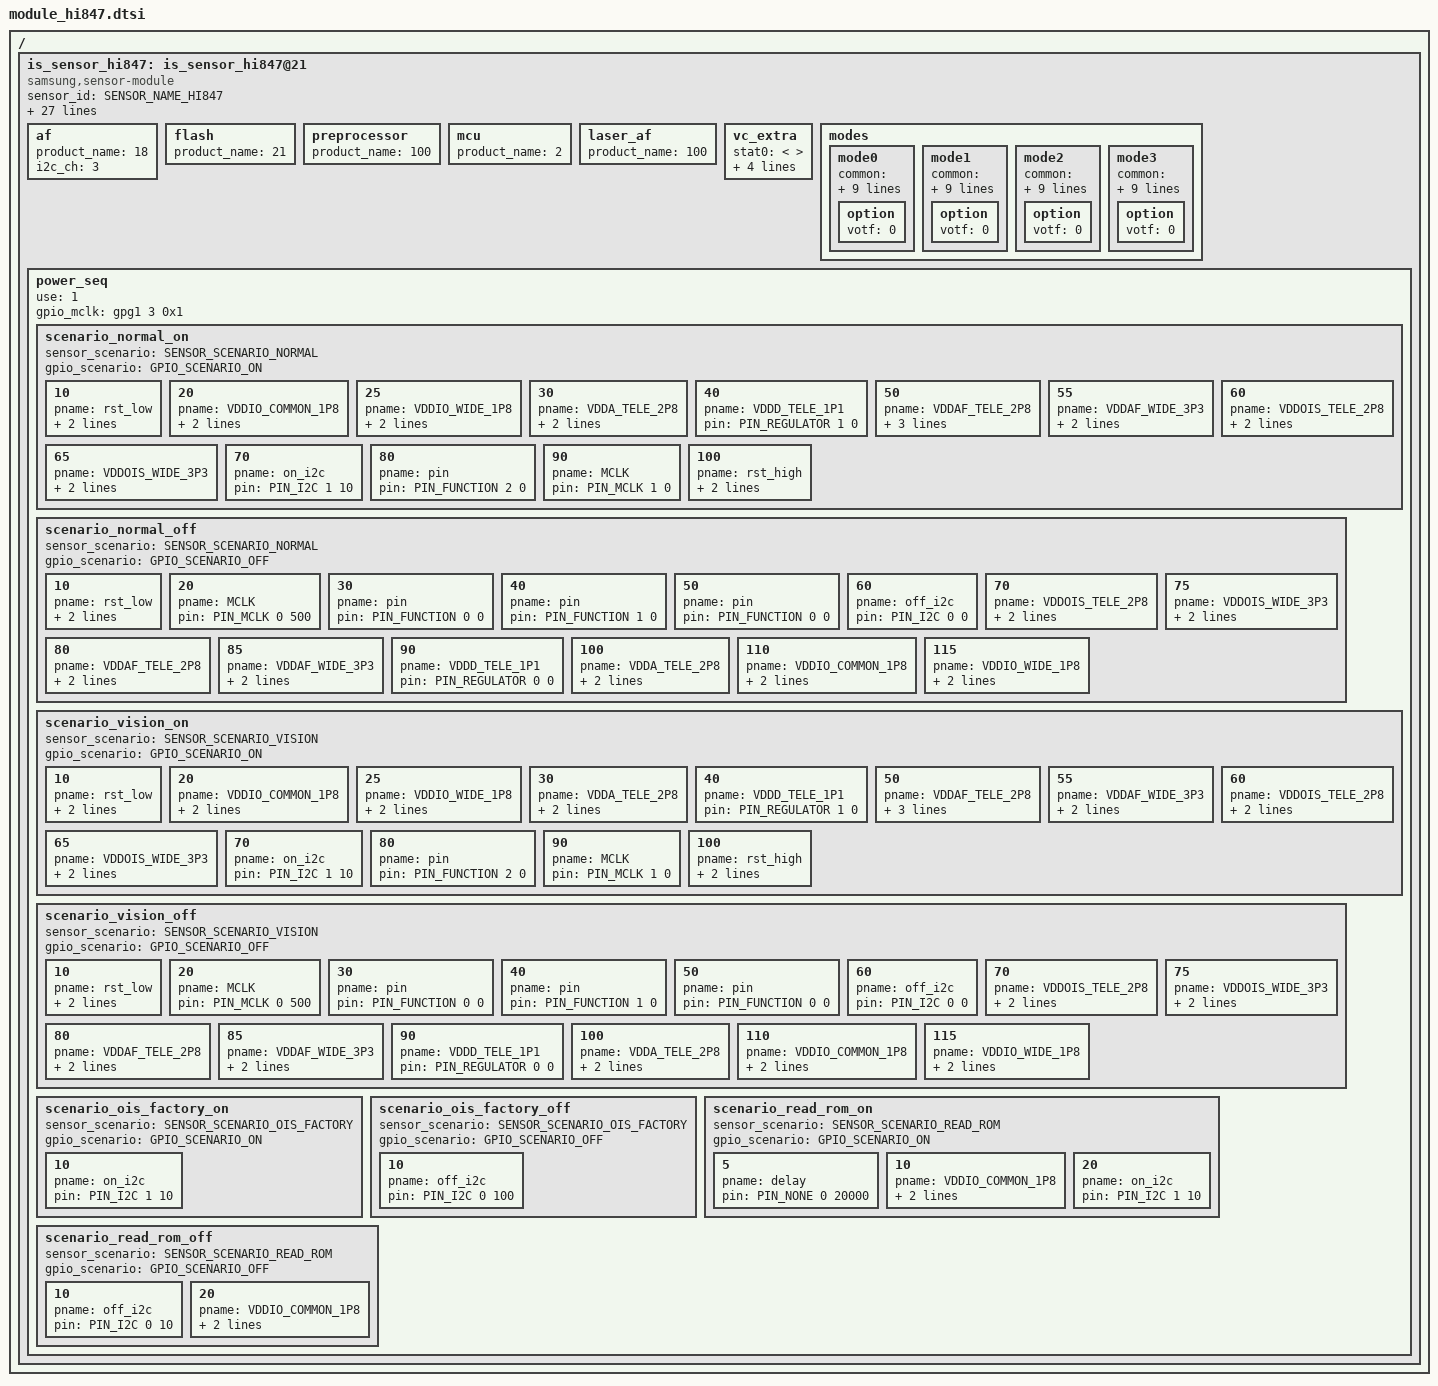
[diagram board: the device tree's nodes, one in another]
/*
 * SAMSUNG EXYNOSxxxx board camera device tree source
 *
 * Copyright (c) 2023 Samsung Electronics Co., Ltd.
 *		http://www.samsung.com
 *
 * This program is free software; you can redistribute it and/or modify
 * it under the terms of the GNU General Public License version 2 as
 * published by the Free Software Foundation.
 */

#include <dt-bindings/camera/exynos_is_dt.h>

/ {
	fragment@camera {
		target-path = "/";
		__overlay__ {
			is_sensor_hi847: is_sensor_hi847@21 {
				compatible = "samsung,sensor-module";

				/* common */
				sensor_id = <SENSOR_NAME_HI847>;
				active_width = <3264>;
				active_height = <2448>;
				margin_left = <0>;
				margin_right = <0>;
				margin_top = <0>;
				margin_bottom = <0>;
				max_framerate = <60>;
				bitwidth = <10>;
				use_retention_mode = <SENSOR_RETENTION_UNSUPPORTED>;
				sensor_maker = "HYNIX";
				sensor_name = "HI847";
				setfile_name = "setfile_hi847.bin";

				status = "okay";

				/* board */
				pinctrl-names = "pin0", "pin1", "pin2", "release";
				pinctrl-0 = <>;
				pinctrl-1 = <&sensor_mclk3_out>;
				pinctrl-2 = <&sensor_mclk3_fn>;
				pinctrl-3 = <>;

				position = <2>; /* Rear:0. Front:1, Tele:2 */
				id = <2>; /* is_sensor id */
				mclk_ch = <3>;
				mclk_freq = <19200>;
				sensor_i2c_ch = <2>; /* SENSOR_CONTROL_I2C2 */

				/* vendor */
				rom_type = <2>; /* ROM_TYPE_EEPROM */
				rom_id = <4>;
				rom_cal_index = <0>;
				rom_dualcal_id = <4>;
				rom_dualcal_index = <0>;

				/* peri */
				af {
					product_name = <18>; /* ACTUATOR_NAME_AK737X */
					i2c_ch = <3>; /* SENSOR_CONTROL_I2C3 */
				};

				flash {
					product_name = <21>;  /* AW36518 */
				};

				preprocessor {
					product_name = <100>; /* NOTHING */
				};

				mcu {
					product_name = <2>; /* INTERNAL */
				};

				laser_af {
					product_name = <100>; /* NOTHING */
				};

				vc_extra {
					/* ex) statX = <stat_type, sensor_mode, max_width, max_height, max_element> */
					stat0 = </* not available */>; /* VC_BUF_DATA_TYPE_SENSOR_STAT1 */
					stat1 = </*VC_STAT_TYPE_PDP_4_1_PDAF_STAT0*/ 1200 /*VC_SENSOR_MODE_ULTRA_PD_3_TAIL*/ 305 200 600 2>;
					stat2 = </* not available */>; /* VC_BUF_DATA_TYPE_SENSOR_STAT2 */
					stat3 = </*VC_STAT_TYPE_PDP_4_1_PDAF_STAT1*/ 1201 /*VC_SENSOR_MODE_ULTRA_PD_3_TAIL*/ 305 200 600 2>;
					stat_vc = <2>; /* STAT out VC after CSIS link */
				};

				/* HI847 sensor setting version -  */
				/* sensor modes */
				modes {
						/* common = <width, height, fps, settle, mode, lane, speed, interleave, lrte, pd_mode> */
						/* vcX = <map, hwformat, width, height, hwformat, type, width, height> */
					mode0 {/* A-1 */
						common = <3264 2448 30 0 0 CSI_DATA_LANES_4 912 CSI_MODE_VC_ONLY LRTE_DISABLE PD_MSPD_TAIL EX_NONE>;
						vc0 = </* in */ 0 HW_FORMAT_RAW10 3264 2448    /* out */ HW_FORMAT_RAW10 VC_NOTHING 3264 2448>;
						vc1 = </* in */ 2 HW_FORMAT_UNKNOWN 0 0        /* out */ HW_FORMAT_UNKNOWN VC_NOTHING 0 0>;
						vc2 = </* in */ 1 HW_FORMAT_RAW10_POTF 200 600      /* out */ HW_FORMAT_RAW10_POTF VC_TAILPDAF 200 600>;
						vc3 = </* in */ 3 HW_FORMAT_UNKNOWN 0 0        /* out */ HW_FORMAT_UNKNOWN VC_NOTHING 0 0>;
						option { votf = <0>; };
					};
					mode1 {/* K-1 */
						common = <3264 1836 30 0 1 CSI_DATA_LANES_4 912 CSI_MODE_VC_ONLY LRTE_DISABLE PD_MSPD_TAIL EX_NONE>;
						vc0 = </* in */ 0 HW_FORMAT_RAW10 3264 1836    /* out */ HW_FORMAT_RAW10 VC_NOTHING 3264 1836>;
						vc1 = </* in */ 2 HW_FORMAT_UNKNOWN 0 0        /* out */ HW_FORMAT_UNKNOWN VC_NOTHING 0 0>;
						vc2 = </* in */ 1 HW_FORMAT_RAW10_POTF 200 448      /* out */ HW_FORMAT_RAW10_POTF VC_TAILPDAF 200 448>;
						vc3 = </* in */ 3 HW_FORMAT_UNKNOWN 0 0        /* out */ HW_FORMAT_UNKNOWN VC_NOTHING 0 0>;
						option { votf = <0>; };
					};
					mode2 {/* N-1 */
						common = <1632 1224 30 0 2 CSI_DATA_LANES_4 456 CSI_MODE_VC_ONLY LRTE_DISABLE PD_NONE>;
						vc0 = </* in */ 0 HW_FORMAT_RAW10 1632 1224    /* out */ HW_FORMAT_RAW10 VC_NOTHING 1632 1224>;
						vc1 = </* in */ 1 HW_FORMAT_UNKNOWN 0 0        /* out */ HW_FORMAT_UNKNOWN VC_NOTHING 0 0>;
						vc2 = </* in */ 2 HW_FORMAT_UNKNOWN 0 0        /* out */ HW_FORMAT_UNKNOWN VC_NOTHING 0 0>;
						vc3 = </* in */ 3 HW_FORMAT_UNKNOWN 0 0        /* out */ HW_FORMAT_UNKNOWN VC_NOTHING 0 0>;
						option { votf = <0>; };
					};
					mode3 {/* J-1 */
						common = <1632 1224 60 0 3 CSI_DATA_LANES_4 456 CSI_MODE_VC_ONLY LRTE_DISABLE PD_NONE>;
						vc0 = </* in */ 0 HW_FORMAT_RAW10 1632 1224    /* out */ HW_FORMAT_RAW10 VC_NOTHING 1632 1224>;
						vc1 = </* in */ 1 HW_FORMAT_UNKNOWN 0 0        /* out */ HW_FORMAT_UNKNOWN VC_NOTHING 0 0>;
						vc2 = </* in */ 2 HW_FORMAT_UNKNOWN 0 0        /* out */ HW_FORMAT_UNKNOWN VC_NOTHING 0 0>;
						vc3 = </* in */ 3 HW_FORMAT_UNKNOWN 0 0        /* out */ HW_FORMAT_UNKNOWN VC_NOTHING 0 0>;
						option { votf = <0>; };
					};
				};

				power_seq {
					use = <1>;
					gpio_mclk = <&gpg1 3 0x1>;
					scenario_normal_on {
						sensor_scenario = <SENSOR_SCENARIO_NORMAL>;
						gpio_scenario = <GPIO_SCENARIO_ON>;

						/* A start node number should be over the 10 for reserved number 0~9. */
						/* pname = "name"; pin = <act value delay voltage>; gpio = <gpx# # 0x1>; */
						10 { pname = "rst_low"; pin = <PIN_OUTPUT 0 0>; gpio = <&gpp7 3 0x1>; };
						20 { pname = "VDDIO_COMMON_1P8"; pin = <PIN_REGULATOR 1 0>; share = <SRT_ACQUIRE SHARED_PIN1 1>; };
						25 { pname = "VDDIO_WIDE_1P8"; pin = <PIN_REGULATOR 1 0>; share = <SRT_ACQUIRE SHARED_PIN0 1>; };
						30 { pname = "VDDA_TELE_2P8"; pin = <PIN_OUTPUT 1 0>; gpio = <&gpm2 1 0x1>; };
						40 { pname = "VDDD_TELE_1P1"; pin = <PIN_REGULATOR 1 0>; };
						50 { pname = "VDDAF_TELE_2P8"; pin = <PIN_REGULATOR 1 2000>; actuator_i2c_delay = <10000>; share = <SRT_ACQUIRE SHARED_PIN3 1>; };
						55 { pname = "VDDAF_WIDE_3P3"; pin = <PIN_REGULATOR 1 1>; share = <SRT_ACQUIRE SHARED_PIN2 1>; };
						60 { pname = "VDDOIS_TELE_2P8"; pin = <PIN_REGULATOR 1 0>; share = <SRT_ACQUIRE SHARED_PIN5 1>; };
						65 { pname = "VDDOIS_WIDE_3P3"; pin = <PIN_REGULATOR 1 100>; share = <SRT_ACQUIRE SHARED_PIN4 1>; };
						70 { pname = "on_i2c"; pin = <PIN_I2C 1 10>; };
						80 { pname = "pin"; pin = <PIN_FUNCTION 2 0>; };
						90 { pname = "MCLK"; pin = <PIN_MCLK 1 0>; };
						100 { pname = "rst_high"; pin = <PIN_OUTPUT 1 200>; gpio = <&gpp7 3 0x1>; };
					};

					scenario_normal_off {
						sensor_scenario = <SENSOR_SCENARIO_NORMAL>;
						gpio_scenario = <GPIO_SCENARIO_OFF>;

						/* A start node number should be over the 10 for reserved number 0~9. */
						/* pname = "name"; pin = <act value delay voltage>; gpio = <gpx# # 0x1>; */
						10 { pname = "rst_low"; pin = <PIN_OUTPUT 0 1000>; gpio = <&gpp7 3 0x1>; };
						20 { pname = "MCLK"; pin = <PIN_MCLK 0 500>; };
						30 { pname = "pin"; pin = <PIN_FUNCTION 0 0>; };
						40 { pname = "pin"; pin = <PIN_FUNCTION 1 0>; };
						50 { pname = "pin"; pin = <PIN_FUNCTION 0 0>; };
						60 { pname = "off_i2c"; pin = <PIN_I2C 0 0>; };
						70 { pname = "VDDOIS_TELE_2P8"; pin = <PIN_REGULATOR 0 0>; share = <SRT_RELEASE SHARED_PIN5 0>; };
						75 { pname = "VDDOIS_WIDE_3P3"; pin = <PIN_REGULATOR 0 100>; share = <SRT_RELEASE SHARED_PIN4 0>; };
						80 { pname = "VDDAF_TELE_2P8"; pin = <PIN_REGULATOR 0 0>; share = <SRT_RELEASE SHARED_PIN3 0>; };
						85 { pname = "VDDAF_WIDE_3P3"; pin = <PIN_REGULATOR 0 1000>; share = <SRT_RELEASE SHARED_PIN2 0>; };
						90 { pname = "VDDD_TELE_1P1"; pin = <PIN_REGULATOR 0 0>; };
						100 { pname = "VDDA_TELE_2P8"; pin = <PIN_OUTPUT 0 0>; gpio = <&gpm2 1 0x1>; };
						110 { pname = "VDDIO_COMMON_1P8"; pin = <PIN_REGULATOR 0 0>; share = <SRT_RELEASE SHARED_PIN1 0>; };
						115 { pname = "VDDIO_WIDE_1P8"; pin = <PIN_REGULATOR 0 10>; share = <SRT_RELEASE SHARED_PIN0 0>; };
					};

					scenario_vision_on {
						sensor_scenario = <SENSOR_SCENARIO_VISION>;
						gpio_scenario = <GPIO_SCENARIO_ON>;

						/* A start node number should be over the 10 for reserved number 0~9. */
						/* pname = "name"; pin = <act value delay voltage>; gpio = <gpx# # 0x1>; */
						10 { pname = "rst_low"; pin = <PIN_OUTPUT 0 0>; gpio = <&gpp7 3 0x1>; };
						20 { pname = "VDDIO_COMMON_1P8"; pin = <PIN_REGULATOR 1 0>; share = <SRT_ACQUIRE SHARED_PIN1 1>; };
						25 { pname = "VDDIO_WIDE_1P8"; pin = <PIN_REGULATOR 1 0>; share = <SRT_ACQUIRE SHARED_PIN0 1>; };
						30 { pname = "VDDA_TELE_2P8"; pin = <PIN_OUTPUT 1 0>; gpio = <&gpm2 1 0x1>; };
						40 { pname = "VDDD_TELE_1P1"; pin = <PIN_REGULATOR 1 0>; };
						50 { pname = "VDDAF_TELE_2P8"; pin = <PIN_REGULATOR 1 2000>; actuator_i2c_delay = <10000>; share = <SRT_ACQUIRE SHARED_PIN3 1>; };
						55 { pname = "VDDAF_WIDE_3P3"; pin = <PIN_REGULATOR 1 1>; share = <SRT_ACQUIRE SHARED_PIN2 1>; };
						60 { pname = "VDDOIS_TELE_2P8"; pin = <PIN_REGULATOR 1 0>; share = <SRT_ACQUIRE SHARED_PIN5 1>; };
						65 { pname = "VDDOIS_WIDE_3P3"; pin = <PIN_REGULATOR 1 100>; share = <SRT_ACQUIRE SHARED_PIN4 1>; };
						70 { pname = "on_i2c"; pin = <PIN_I2C 1 10>; };
						80 { pname = "pin"; pin = <PIN_FUNCTION 2 0>; };
						90 { pname = "MCLK"; pin = <PIN_MCLK 1 0>; };
						100 { pname = "rst_high"; pin = <PIN_OUTPUT 1 200>; gpio = <&gpp7 3 0x1>; };
					};

					scenario_vision_off {
						sensor_scenario = <SENSOR_SCENARIO_VISION>;
						gpio_scenario = <GPIO_SCENARIO_OFF>;

						/* A start node number should be over the 10 for reserved number 0~9. */
						/* pname = "name"; pin = <act value delay voltage>; gpio = <gpx# # 0x1>; */
						10 { pname = "rst_low"; pin = <PIN_OUTPUT 0 1000>; gpio = <&gpp7 3 0x1>; };
						20 { pname = "MCLK"; pin = <PIN_MCLK 0 500>; };
						30 { pname = "pin"; pin = <PIN_FUNCTION 0 0>; };
						40 { pname = "pin"; pin = <PIN_FUNCTION 1 0>; };
						50 { pname = "pin"; pin = <PIN_FUNCTION 0 0>; };
						60 { pname = "off_i2c"; pin = <PIN_I2C 0 0>; };
						70 { pname = "VDDOIS_TELE_2P8"; pin = <PIN_REGULATOR 0 0>; share = <SRT_RELEASE SHARED_PIN5 0>; };
						75 { pname = "VDDOIS_WIDE_3P3"; pin = <PIN_REGULATOR 0 100>; share = <SRT_RELEASE SHARED_PIN4 0>; };
						80 { pname = "VDDAF_TELE_2P8"; pin = <PIN_REGULATOR 0 0>; share = <SRT_RELEASE SHARED_PIN3 0>; };
						85 { pname = "VDDAF_WIDE_3P3"; pin = <PIN_REGULATOR 0 1000>; share = <SRT_RELEASE SHARED_PIN2 0>; };
						90 { pname = "VDDD_TELE_1P1"; pin = <PIN_REGULATOR 0 0>; };
						100 { pname = "VDDA_TELE_2P8"; pin = <PIN_OUTPUT 0 0>; gpio = <&gpm2 1 0x1>; };
						110 { pname = "VDDIO_COMMON_1P8"; pin = <PIN_REGULATOR 0 0>; share = <SRT_RELEASE SHARED_PIN1 0>; };
						115 { pname = "VDDIO_WIDE_1P8"; pin = <PIN_REGULATOR 0 10>; share = <SRT_RELEASE SHARED_PIN0 0>; };
					};

					scenario_ois_factory_on {
						sensor_scenario = <SENSOR_SCENARIO_OIS_FACTORY>;
						gpio_scenario = <GPIO_SCENARIO_ON>;

						10 { pname = "on_i2c"; pin = <PIN_I2C 1 10>; };
					};

					scenario_ois_factory_off {
						sensor_scenario = <SENSOR_SCENARIO_OIS_FACTORY>;
						gpio_scenario = <GPIO_SCENARIO_OFF>;

						10 { pname = "off_i2c"; pin = <PIN_I2C 0 100>; };
					};

					scenario_read_rom_on {
						sensor_scenario = <SENSOR_SCENARIO_READ_ROM>;
						gpio_scenario = <GPIO_SCENARIO_ON>;

						/* A start node number should be over the 10 for reserved number 0~9. */
						/* pname = "name"; pin = <act value delay voltage>; gpio = <gpx# # 0x1>; */
						5 { pname = "delay"; pin = <PIN_NONE 0 20000>; };
						10 { pname = "VDDIO_COMMON_1P8"; pin = <PIN_REGULATOR 1 5000>; share = <SRT_ACQUIRE SHARED_PIN1 1>; };
						20 { pname = "on_i2c"; pin = <PIN_I2C 1 10>; };
					};

					scenario_read_rom_off {
						sensor_scenario = <SENSOR_SCENARIO_READ_ROM>;
						gpio_scenario = <GPIO_SCENARIO_OFF>;

						/* A start node number should be over the 10 for reserved number 0~9. */
						/* pname = "name"; pin = <act value delay voltage>; gpio = <gpx# # 0x1>; */
						10 { pname = "off_i2c"; pin = <PIN_I2C 0 10>; };
						20 { pname = "VDDIO_COMMON_1P8"; pin = <PIN_REGULATOR 0 40000>; share = <SRT_RELEASE SHARED_PIN1 0>; };
					};
				};
			};
		}; /* end of __overlay__ */
	}; /* end of fragment */
}; /* end of root */
